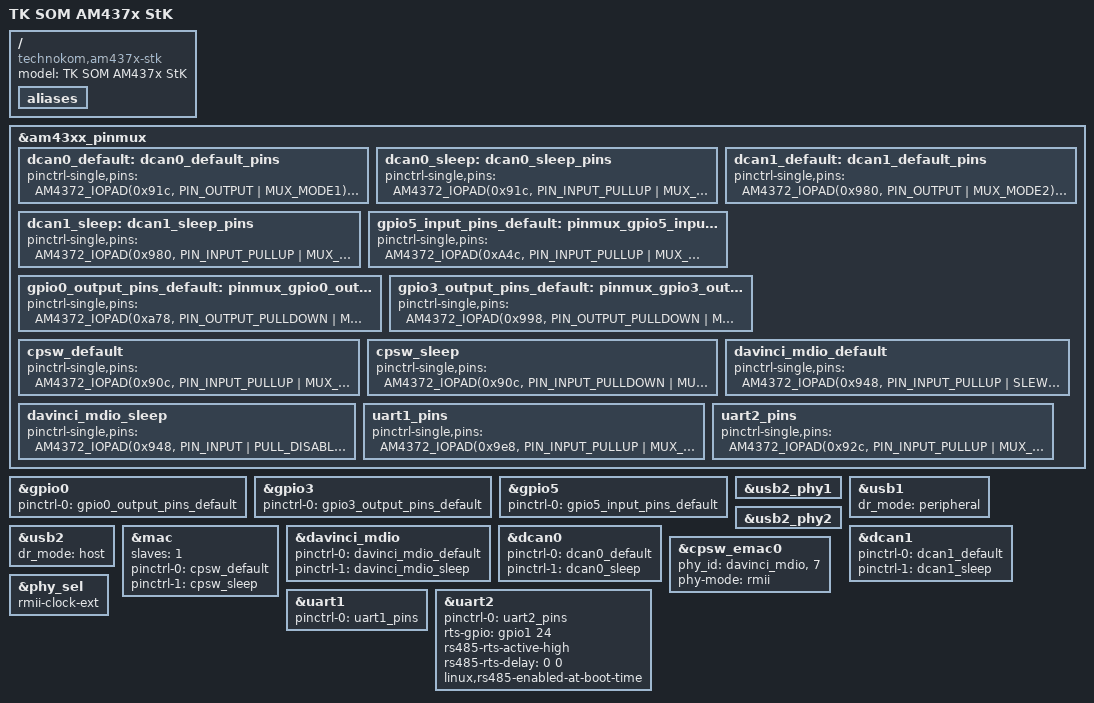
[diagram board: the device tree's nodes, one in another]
/*
 * Copyright (C) 2018 Technokom Incorporated - http://www.tk-nav.ru
 *
 * This program is free software; you redistribute it and/or modify
 * it under the terms of the GNU General Public License version 2 as
 * published by the Free Software Foundation.
 */

/* TK SOM AM437x StK */

/dts-v1/;

#include "am4372.dtsi"
#include "tk-som-am43xx.dtsi"
#include <dt-bindings/pinctrl/am43xx.h>
#include <dt-bindings/pwm/pwm.h>
#include <dt-bindings/gpio/gpio.h>
#include <dt-bindings/input/input.h>

/ {
	model = "TK SOM AM437x StK";
	compatible = "technokom,am437x-stk","ti,am4372","ti,am43";

	aliases {

	};

};

&am43xx_pinmux {
	pinctrl-names = "default", "sleep";

	dcan0_default: dcan0_default_pins {
		pinctrl-single,pins = <
			AM4372_IOPAD(0x91c, PIN_OUTPUT | MUX_MODE1)		/* (C16) mii1_txd3.dcan0_tx */
			AM4372_IOPAD(0x920, PIN_INPUT_PULLUP | MUX_MODE1)	/* (C13) mii1_txd2.dcan0_rx */
		>;
	};

	dcan0_sleep: dcan0_sleep_pins {
		pinctrl-single,pins = <
			AM4372_IOPAD(0x91c, PIN_INPUT_PULLUP | MUX_MODE7)	/* (C16) mii1_txd3 */
			AM4372_IOPAD(0x920, PIN_INPUT_PULLUP | MUX_MODE7)	/* (C13) mii1_txd2 */
		>;
	};

	dcan1_default: dcan1_default_pins {
		pinctrl-single,pins = <
			AM4372_IOPAD(0x980, PIN_OUTPUT | MUX_MODE2)		/* uart1_rxd.d_can1_tx */
			AM4372_IOPAD(0x984, PIN_INPUT_PULLUP | MUX_MODE2)	/* uart1_txd.d_can1_rx */
		>;
	};

	dcan1_sleep: dcan1_sleep_pins {
		pinctrl-single,pins = <
			AM4372_IOPAD(0x980, PIN_INPUT_PULLUP | MUX_MODE7)	/* uart1_rxd.gpio0_14 */
			AM4372_IOPAD(0x984, PIN_INPUT_PULLUP | MUX_MODE7)	/* uart1_txd.gpio0_15 */
		>;
	};

    gpio5_input_pins_default: pinmux_gpio5_input_pins_default {
		pinctrl-single,pins = <
            AM4372_IOPAD(0xA4c, PIN_INPUT_PULLUP | MUX_MODE7) /* (E24) gpio5_13.gpio5[13] */
		    AM4372_IOPAD(0xA74, PIN_INPUT_PULLUP | MUX_MODE9) /* (C24) xdma_event_intr1.gpio5[29] */
		>;
    };


    gpio0_output_pins_default: pinmux_gpio0_output_pins_default {
		pinctrl-single,pins = <
            AM4372_IOPAD(0xa78, PIN_OUTPUT_PULLDOWN | MUX_MODE7 ) /* (H20) clkreq.gpio0[24] */
		>;
    };


    gpio3_output_pins_default: pinmux_gpio3_output_pins_default {
		pinctrl-single,pins = <
            AM4372_IOPAD(0x998, PIN_OUTPUT_PULLDOWN | MUX_MODE7 ) /* (H23) mcasp0_axr0.gpio3[16] */
		>;
    };

	cpsw_default: cpsw_default {
		pinctrl-single,pins = <
			AM4372_IOPAD(0x90c, PIN_INPUT_PULLUP | MUX_MODE1 ) /* (B14) mii1_crs.rmii1_crs_dv */
			AM4372_IOPAD(0x910, PIN_INPUT_PULLUP | MUX_MODE1 ) /* (B13) mii1_rx_er.rmii1_rxer */
			AM4372_IOPAD(0x914, PIN_OUTPUT_PULLDOWN | MUX_MODE1 ) /* (A13) mii1_tx_en.rmii1_txen */
			AM4372_IOPAD(0x928, PIN_OUTPUT_PULLDOWN | MUX_MODE1 ) /* (B15) mii1_txd0.rmii1_txd0 */
			AM4372_IOPAD(0x924, PIN_OUTPUT_PULLDOWN | MUX_MODE1 ) /* (A14) mii1_txd1.rmii1_txd1 */
			AM4372_IOPAD(0x940, PIN_INPUT | MUX_MODE1 ) /* (F17) mii1_rxd0.rmii1_rxd0 */
			AM4372_IOPAD(0x93c, PIN_INPUT | MUX_MODE1 ) /* (B16) mii1_rxd1.rmii1_rxd1 */
			AM4372_IOPAD(0x944, PIN_INPUT_PULLUP | MUX_MODE0 ) /* (A16) rmii1_ref_clk.rmii1_refclk */

		>;
	};

	cpsw_sleep: cpsw_sleep {
		pinctrl-single,pins = <
			AM4372_IOPAD(0x90c, PIN_INPUT_PULLDOWN | MUX_MODE7 )
			AM4372_IOPAD(0x910, PIN_INPUT_PULLDOWN | MUX_MODE7 )
			AM4372_IOPAD(0x914, PIN_INPUT_PULLDOWN | MUX_MODE7 )
			AM4372_IOPAD(0x928, PIN_INPUT_PULLDOWN | MUX_MODE7 )
			AM4372_IOPAD(0x924, PIN_INPUT_PULLDOWN | MUX_MODE7 )
			AM4372_IOPAD(0x940, PIN_INPUT_PULLDOWN | MUX_MODE7 )
			AM4372_IOPAD(0x93c, PIN_INPUT_PULLDOWN | MUX_MODE7 )
			AM4372_IOPAD(0x944, PIN_INPUT_PULLDOWN | MUX_MODE7 )
		>;
	};

	davinci_mdio_default: davinci_mdio_default {
		pinctrl-single,pins = <
			/* MDIO */
			AM4372_IOPAD(0x948, PIN_INPUT_PULLUP | SLEWCTRL_FAST | MUX_MODE0)	/* mdio_data.mdio_data */
			AM4372_IOPAD(0x94c, PIN_OUTPUT_PULLUP | MUX_MODE0)			/* mdio_clk.mdio_clk */
		>;
	};

	davinci_mdio_sleep: davinci_mdio_sleep {
		pinctrl-single,pins = <
			/* MDIO reset value */
			AM4372_IOPAD(0x948, PIN_INPUT | PULL_DISABLE | MUX_MODE7)
			AM4372_IOPAD(0x94c, PIN_INPUT | PULL_DISABLE | MUX_MODE7)
		>;
	};
	

	uart1_pins: uart1_pins {
		pinctrl-single,pins = <
			AM4372_IOPAD(0x9e8, PIN_INPUT_PULLUP | MUX_MODE1 ) /* (AB20) cam1_data0.uart1_rxd */
			AM4372_IOPAD(0x9ec, PIN_OUTPUT_PULLDOWN | MUX_MODE1 ) /* (AC21) cam1_data1.uart1_txd */
		>;
	};

    uart2_pins: uart2_pins {
        pinctrl-single,pins = <
		    AM4372_IOPAD(0x92c, PIN_INPUT_PULLUP | MUX_MODE1 ) /* (D14) mii1_tx_clk.uart2_rxd */
    		AM4372_IOPAD(0x930, PIN_OUTPUT_PULLDOWN | MUX_MODE1 ) /* (D13) mii1_rx_clk.uart2_txd */
    		AM4372_IOPAD(0x860,  PIN_OUTPUT_PULLDOWN | MUX_MODE7 ) /* (F7) gpmc_a8.gpio1[24] */
	    >;
    };

};

&gpio0 {
	pinctrl-0 = <&gpio0_output_pins_default>;
};

&gpio3 {
	pinctrl-0 = <&gpio3_output_pins_default>;
};

&gpio5 {
	pinctrl-0 = <&gpio5_input_pins_default>;
};

&usb2_phy1 {
	status = "okay";
};

&usb1 {
	dr_mode = "peripheral";
	status = "okay";
};

&usb2_phy2 {
	status = "okay";
};

&usb2 {
	dr_mode = "host";
	status = "okay";
};

&mac {
	slaves = <1>;
	pinctrl-names = "default", "sleep";
	pinctrl-0 = <&cpsw_default>;
	pinctrl-1 = <&cpsw_sleep>;
	status = "okay";
};

&davinci_mdio {
	pinctrl-names = "default", "sleep";
	pinctrl-0 = <&davinci_mdio_default>;
	pinctrl-1 = <&davinci_mdio_sleep>;
	status = "okay";
};

&dcan0 {
	pinctrl-names = "default", "sleep";
	pinctrl-0 = <&dcan0_default>;
	pinctrl-1 = <&dcan0_sleep>;
	status = "okay";
};

&dcan1 {
	pinctrl-names = "default", "sleep";
	pinctrl-0 = <&dcan1_default>;
	pinctrl-1 = <&dcan1_sleep>;
	status = "okay";
};

&cpsw_emac0 {
	phy_id = <&davinci_mdio>, <7>;
	phy-mode = "rmii";
};

&phy_sel {
	rmii-clock-ext;
};

&uart1 {
	status = "okay";
	pinctrl-names = "default";
	pinctrl-0 = <&uart1_pins>;
};


&uart2 {
	status = "okay";
	pinctrl-names = "default";
	pinctrl-0 = <&uart2_pins>;
    rts-gpio = <&gpio1 24 GPIO_ACTIVE_HIGH>;
    rs485-rts-active-high;
    rs485-rts-delay = <0 0>;
    linux,rs485-enabled-at-boot-time;
};

